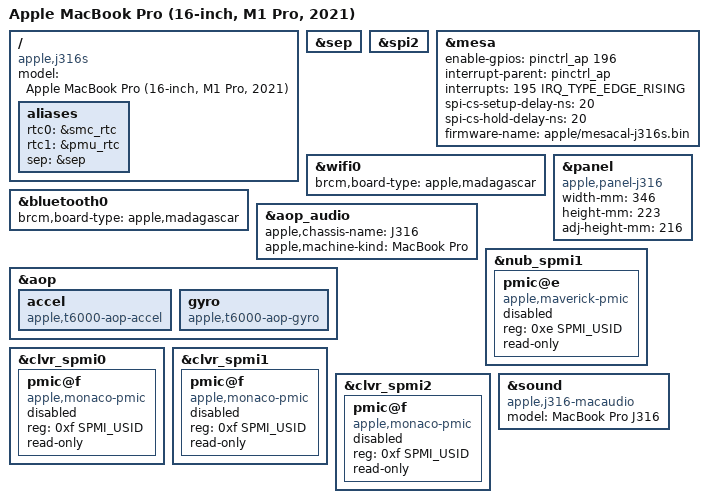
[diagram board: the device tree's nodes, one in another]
// SPDX-License-Identifier: GPL-2.0+ OR MIT
/*
 * MacBook Pro (16-inch, M1 Pro, 2021)
 *
 * target-type: J316s
 *
 * Copyright The Asahi Linux Contributors
 */

/dts-v1/;

/*
 * PMP manages system power states, as on the J314s: the ANE, GPU, AVD and
 * JPEG send it their performance requests, and the board idles lower.
 */
#define APPLE_USE_PMP

#include "t6000.dtsi"
#include "t600x-j314-j316.dtsi"
#include "t6000-hwmon-rails.dtsi"

/ {
	compatible = "apple,j316s", "apple,t6000", "apple,arm-platform";
	model = "Apple MacBook Pro (16-inch, M1 Pro, 2021)";

	aliases {
		rtc0 = &smc_rtc;
		rtc1 = &pmu_rtc;
		sep = &sep;
	};
};

/*
 * m1n1 keys off the sep alias to add the sepfw region and the boot
 * manifests the driver needs to cold-boot SEPOS.
 */
&sep {
	status = "okay";
};

/*
 * From the J316s platform device tree (/arm-io/spi2/mesa): the power line
 * is gpio0 pin 196 (function-mesa_pwr, active high) and the data-ready line
 * is pin 195. J414s's lines, 122 and 121, read the same way from its tree.
 */
&spi2 {
	status = "okay";
};

&mesa {
	status = "okay";
	enable-gpios = <&pinctrl_ap 196 GPIO_ACTIVE_HIGH>;
	interrupt-parent = <&pinctrl_ap>;
	interrupts = <195 IRQ_TYPE_EDGE_RISING>;
	spi-cs-setup-delay-ns = <20>;
	spi-cs-hold-delay-ns = <20>;
	/*
	 * Per-device factory data, extracted from this machine's own macOS
	 * install; it is not redistributable.
	 */
	firmware-name = "apple/mesacal-j316s.bin";
};

&wifi0 {
	brcm,board-type = "apple,madagascar";
};

&bluetooth0 {
	brcm,board-type = "apple,madagascar";
};

&panel {
	compatible = "apple,panel-j316", "apple,panel-mini-led", "apple,panel";
	width-mm = <346>;
	height-mm = <223>;
	adj-height-mm = <216>;
};

&aop_audio {
	apple,chassis-name = "J316";
	apple,machine-kind = "MacBook Pro";
};

&aop {
	accel {
		compatible = "apple,t6000-aop-accel", "apple,aop-accel";
	};

	gyro {
		compatible = "apple,t6000-aop-gyro", "apple,aop-gyro";
	};
};

&nub_spmi1 {
	pmic@e {
		compatible = "apple,maverick-pmic", "apple,spmi-nvmem";
		reg = <0xe SPMI_USID>;
		read-only;
		status = "disabled";
	};
};

&clvr_spmi0 {
	pmic@f {
		compatible = "apple,monaco-pmic", "apple,spmi-nvmem";
		reg = <0xf SPMI_USID>;
		read-only;
		status = "disabled";
	};
};

&clvr_spmi1 {
	pmic@f {
		compatible = "apple,monaco-pmic", "apple,spmi-nvmem";
		reg = <0xf SPMI_USID>;
		read-only;
		status = "disabled";
	};
};

&clvr_spmi2 {
	pmic@f {
		compatible = "apple,monaco-pmic", "apple,spmi-nvmem";
		reg = <0xf SPMI_USID>;
		read-only;
		status = "disabled";
	};
};

&sound {
	compatible = "apple,j316-macaudio", "apple,macaudio";
	model = "MacBook Pro J316";
};
